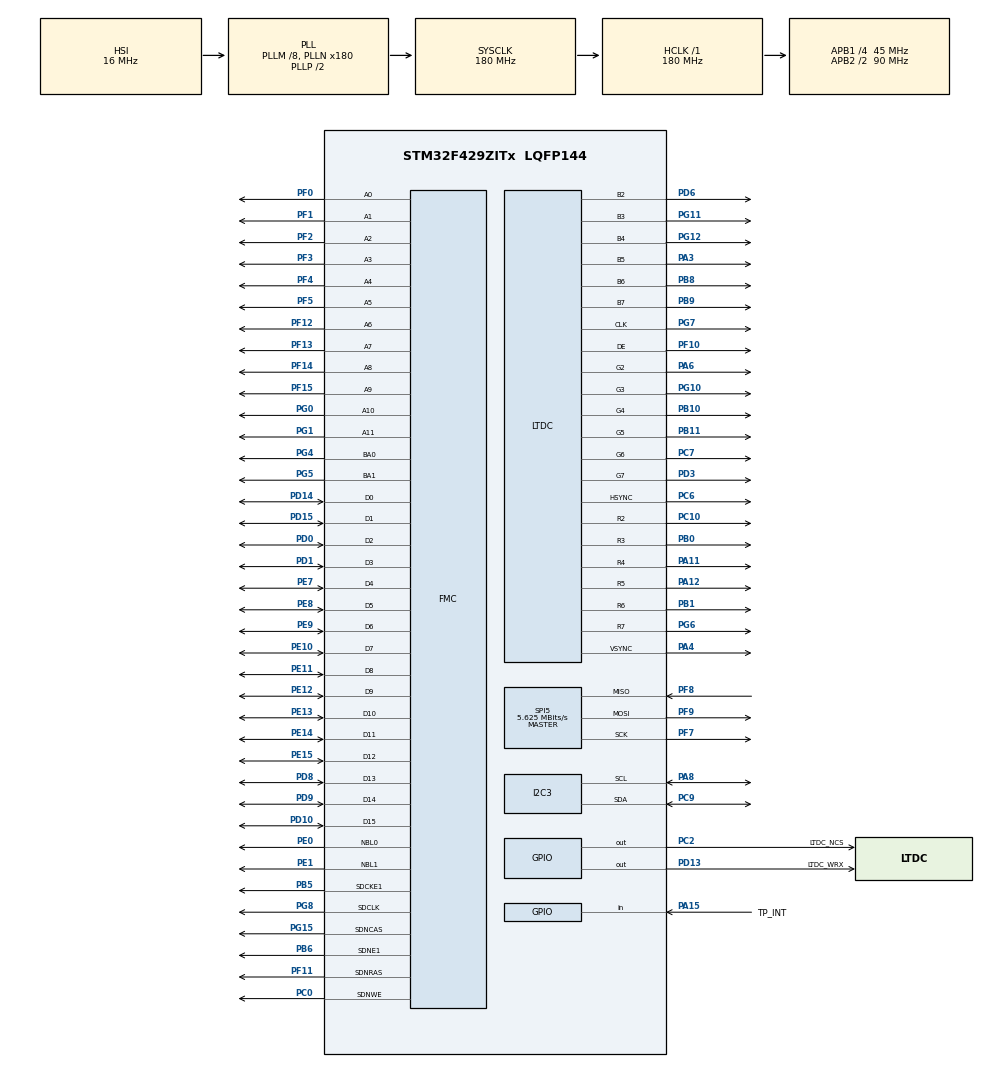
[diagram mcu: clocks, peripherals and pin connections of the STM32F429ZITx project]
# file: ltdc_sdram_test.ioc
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DMA2D.AlphaModeBackground=DMA2D_REPLACE_ALPHA
DMA2D.AlphaModeForeground=DMA2D_REPLACE_ALPHA
DMA2D.ColorMode=DMA2D_OUTPUT_RGB888
DMA2D.InputColorModeBackground=DMA2D_INPUT_RGB888
DMA2D.InputColorModeForeground=DMA2D_INPUT_RGB888
DMA2D.Mode=DMA2D_M2M_BLEND
FMC.CASLatency1=FMC_SDRAM_CAS_LATENCY_3
FMC.ExitSelfRefreshDelay1=7
FMC.LoadToActiveDelay1=2
FMC.RCDDelay1=2
FMC.RPDelay1=2
FMC.RPDelay2=2
FMC.ReadPipeDelay1=FMC_SDRAM_RPIPE_DELAY_1
FMC.ReadPipeDelay2=FMC_SDRAM_RPIPE_DELAY_1
FMC.RowCycleDelay1=7
FMC.RowCycleDelay2=7
FMC.SDClockPeriod1=FMC_SDRAM_CLOCK_PERIOD_2
FMC.SDClockPeriod2=FMC_SDRAM_CLOCK_PERIOD_2
FMC.SelfRefreshTime1=4
FMC.WriteRecoveryTime1=3
FREERTOS.Tasks01=defaultTask,0,128,StartDefaultTask,Default,NULL
I2C3.OwnAddress=0x41
LTDC.ActiveH=320
LTDC.ActiveW=240
LTDC.Alpha_L0=255
LTDC.BlendingFactor1_L0=LTDC_BLENDING_FACTOR1_CA
LTDC.BlendingFactor2_L0=LTDC_BLENDING_FACTOR2_CA
LTDC.HBP=21
LTDC.HFP=10
LTDC.HSync=9
LTDC.ImageHeight_L0=320
LTDC.ImageWidth_L0=240
LTDC.Layers=0
LTDC.PixelFormat_L0=LTDC_PIXEL_FORMAT_RGB888
LTDC.VBP=3
LTDC.VFP=4
LTDC.VSync=1
LTDC.WindowX1_L0=240
LTDC.WindowY1_L0=320
Mcu.Family=STM32F4
Mcu.Name=STM32F429ZITx
Mcu.Package=LQFP144
NVIC.DMA2D_IRQn=true\:5\:0\:false\:false\:true\:true\:true
NVIC.PriorityGroup=NVIC_PRIORITYGROUP_4
PA11.GPIO_Speed=GPIO_SPEED_FREQ_HIGH
PA11.Mode=RGB666
PA11.Signal=LTDC_R4
PA12.GPIO_Speed=GPIO_SPEED_FREQ_HIGH
PA12.Mode=RGB666
PA12.Signal=LTDC_R5
PA13.Mode=Serial_Wire
PA13.Signal=SYS_JTMS-SWDIO
PA14.Mode=Serial_Wire
PA14.Signal=SYS_JTCK-SWCLK
PA15.GPIO_Label=TP_INT
PA15.Signal=GPIO_Input
PA3.GPIO_Speed=GPIO_SPEED_FREQ_HIGH
PA3.Mode=RGB666
PA3.Signal=LTDC_B5
PA4.GPIO_Speed=GPIO_SPEED_FREQ_HIGH
PA4.Mode=RGB666
PA4.Signal=LTDC_VSYNC
PA6.GPIO_Speed=GPIO_SPEED_FREQ_HIGH
PA6.Mode=RGB666
PA6.Signal=LTDC_G2
PA8.Mode=I2C
PA8.Signal=I2C3_SCL
PB0.GPIO_Speed=GPIO_SPEED_FREQ_HIGH
PB0.Mode=RGB666
PB0.Signal=LTDC_R3
PB1.GPIO_Speed=GPIO_SPEED_FREQ_HIGH
PB1.Mode=RGB666
PB1.Signal=LTDC_R6
PB10.GPIO_Speed=GPIO_SPEED_FREQ_HIGH
PB10.Mode=RGB666
PB10.Signal=LTDC_G4
PB11.GPIO_Speed=GPIO_SPEED_FREQ_HIGH
PB11.Mode=RGB666
PB11.Signal=LTDC_G5
PB5.Mode=SdramChipSelect2_1
PB5.Signal=FMC_SDCKE1
PB6.Mode=SdramChipSelect2_1
PB6.Signal=FMC_SDNE1
PB8.GPIO_Speed=GPIO_SPEED_FREQ_HIGH
PB8.Mode=RGB666
PB8.Signal=LTDC_B6
PB9.GPIO_Speed=GPIO_SPEED_FREQ_HIGH
PB9.Mode=RGB666
PB9.Signal=LTDC_B7
PC0.Signal=FMC_SDNWE
PC10.GPIO_Speed=GPIO_SPEED_FREQ_HIGH
PC10.Mode=RGB666
PC10.Signal=LTDC_R2
PC2.GPIO_Label=LTDC_NCS
PC2.GPIO_Speed=GPIO_SPEED_FREQ_HIGH
PC2.PinState=GPIO_PIN_SET
PC2.Signal=GPIO_Output
PC6.GPIO_Speed=GPIO_SPEED_FREQ_HIGH
PC6.Mode=RGB666
PC6.Signal=LTDC_HSYNC
PC7.GPIO_Speed=GPIO_SPEED_FREQ_HIGH
PC7.Mode=RGB666
PC7.Signal=LTDC_G6
PC9.Mode=I2C
PC9.Signal=I2C3_SDA
PD0.Signal=FMC_D2_DA2
PD1.Signal=FMC_D3_DA3
PD10.Signal=FMC_D15_DA15
PD13.GPIO_Label=LTDC_WRX
PD13.GPIO_Speed=GPIO_SPEED_FREQ_HIGH
PD13.Signal=GPIO_Output
PD14.Signal=FMC_D0_DA0
PD15.Signal=FMC_D1_DA1
PD3.GPIO_Speed=GPIO_SPEED_FREQ_HIGH
PD3.Mode=RGB666
PD3.Signal=LTDC_G7
PD6.GPIO_Speed=GPIO_SPEED_FREQ_HIGH
PD6.Mode=RGB666
PD6.Signal=LTDC_B2
PD8.Signal=FMC_D13_DA13
PD9.Signal=FMC_D14_DA14
PE0.Signal=FMC_NBL0
PE1.Signal=FMC_NBL1
PE10.Signal=FMC_D7_DA7
PE11.Signal=FMC_D8_DA8
PE12.Signal=FMC_D9_DA9
PE13.Signal=FMC_D10_DA10
PE14.Signal=FMC_D11_DA11
PE15.Signal=FMC_D12_DA12
PE7.Signal=FMC_D4_DA4
PE8.Signal=FMC_D5_DA5
PE9.Signal=FMC_D6_DA6
PF0.Signal=FMC_A0
PF1.Signal=FMC_A1
PF10.GPIO_Speed=GPIO_SPEED_FREQ_HIGH
PF10.Mode=RGB666
PF10.Signal=LTDC_DE
PF11.Signal=FMC_SDNRAS
PF12.Signal=FMC_A6
PF13.Signal=FMC_A7
PF14.Signal=FMC_A8
PF15.Signal=FMC_A9
PF2.Signal=FMC_A2
PF3.Signal=FMC_A3
PF4.Signal=FMC_A4
PF5.Signal=FMC_A5
PF7.Mode=Full_Duplex_Master
PF7.Signal=SPI5_SCK
PF8.Mode=Full_Duplex_Master
PF8.Signal=SPI5_MISO
PF9.Mode=Full_Duplex_Master
PF9.Signal=SPI5_MOSI
PG0.Signal=FMC_A10
PG1.Signal=FMC_A11
PG10.GPIO_Speed=GPIO_SPEED_FREQ_HIGH
PG10.Mode=RGB666
PG10.Signal=LTDC_G3
PG11.GPIO_Speed=GPIO_SPEED_FREQ_HIGH
PG11.Mode=RGB666
PG11.Signal=LTDC_B3
PG12.GPIO_Speed=GPIO_SPEED_FREQ_HIGH
PG12.Mode=RGB666
PG12.Signal=LTDC_B4
PG15.Signal=FMC_SDNCAS
PG4.Signal=FMC_A14_BA0
PG5.Signal=FMC_A15_BA1
PG6.GPIO_Speed=GPIO_SPEED_FREQ_HIGH
PG6.Mode=RGB666
PG6.Signal=LTDC_R7
PG7.GPIO_Speed=GPIO_SPEED_FREQ_HIGH
PG7.Mode=RGB666
PG7.Signal=LTDC_CLK
PG8.Signal=FMC_SDCLK
ProjectManager.HeapSize=0x2000
ProjectManager.StackSize=0x4000
ProjectManager.TargetToolchain=TrueSTUDIO
RCC.48MHZClocksFreq_Value=90000000
RCC.AHBFreq_Value=180000000
RCC.APB1CLKDivider=RCC_HCLK_DIV4
RCC.APB1Freq_Value=45000000
RCC.APB1TimFreq_Value=90000000
RCC.APB2CLKDivider=RCC_HCLK_DIV2
RCC.APB2Freq_Value=90000000
RCC.APB2TimFreq_Value=180000000
RCC.CortexFreq_Value=180000000
RCC.HCLKFreq_Value=180000000
RCC.HSE_VALUE=25000000
RCC.HSI_VALUE=16000000
RCC.LSE_VALUE=32768
RCC.PLLM=8
RCC.PLLN=180
RCC.PLLSAIDivR=RCC_PLLSAIDIVR_4
RCC.PLLSAIN=60
RCC.SYSCLKFreq_VALUE=180000000
RCC.SYSCLKSource=RCC_SYSCLKSOURCE_PLLCLK
RCC.VCOOutputFreq_Value=360000000
SH.FMC_A0.0=FMC_A0,12b-sda1
SH.FMC_A1.0=FMC_A1,12b-sda1
SH.FMC_A10.0=FMC_A10,12b-sda1
SH.FMC_A11.0=FMC_A11,12b-sda1
SH.FMC_A14_BA0.0=FMC_BA0,FourSdramBanks1
SH.FMC_A15_BA1.0=FMC_BA1,FourSdramBanks1
SH.FMC_A2.0=FMC_A2,12b-sda1
SH.FMC_A3.0=FMC_A3,12b-sda1
SH.FMC_A4.0=FMC_A4,12b-sda1
SH.FMC_A5.0=FMC_A5,12b-sda1
SH.FMC_A6.0=FMC_A6,12b-sda1
SH.FMC_A7.0=FMC_A7,12b-sda1
SH.FMC_A8.0=FMC_A8,12b-sda1
SH.FMC_A9.0=FMC_A9,12b-sda1
SH.FMC_D0_DA0.0=FMC_D0,sd-16b-d1
SH.FMC_D10_DA10.0=FMC_D10,sd-16b-d1
SH.FMC_D11_DA11.0=FMC_D11,sd-16b-d1
SH.FMC_D12_DA12.0=FMC_D12,sd-16b-d1
SH.FMC_D13_DA13.0=FMC_D13,sd-16b-d1
SH.FMC_D14_DA14.0=FMC_D14,sd-16b-d1
SH.FMC_D15_DA15.0=FMC_D15,sd-16b-d1
SH.FMC_D1_DA1.0=FMC_D1,sd-16b-d1
SH.FMC_D2_DA2.0=FMC_D2,sd-16b-d1
SH.FMC_D3_DA3.0=FMC_D3,sd-16b-d1
SH.FMC_D4_DA4.0=FMC_D4,sd-16b-d1
SH.FMC_D5_DA5.0=FMC_D5,sd-16b-d1
SH.FMC_D6_DA6.0=FMC_D6,sd-16b-d1
SH.FMC_D7_DA7.0=FMC_D7,sd-16b-d1
SH.FMC_D8_DA8.0=FMC_D8,sd-16b-d1
SH.FMC_D9_DA9.0=FMC_D9,sd-16b-d1
SH.FMC_NBL0.0=FMC_NBL0,Sd2ByteEnable1
SH.FMC_NBL1.0=FMC_NBL1,Sd2ByteEnable1
SH.FMC_SDCLK.0=FMC_SDCLK,12b-sda1
SH.FMC_SDNCAS.0=FMC_SDNCAS,12b-sda1
SH.FMC_SDNRAS.0=FMC_SDNRAS,12b-sda1
SH.FMC_SDNWE.0=FMC_SDNWE,12b-sda1
SPI5.BaudRatePrescaler=SPI_BAUDRATEPRESCALER_16
SPI5.CalculateBaudRate=5.625 MBits/s
SPI5.Direction=SPI_DIRECTION_2LINES
SPI5.Mode=SPI_MODE_MASTER
SPI5.VirtualType=VM_MASTER
VP_DMA2D_VS_DMA2D.Mode=DMA2D_Activate
VP_FREERTOS_VS_ENABLE.Mode=Enabled
board=custom

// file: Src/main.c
/* USER CODE BEGIN Header */
/**
  ******************************************************************************
  * @file           : main.c
  * @brief          : Main program body
  ******************************************************************************
  ** This notice applies to any and all portions of this file
  * that are not between comment pairs USER CODE BEGIN and
  * USER CODE END. Other portions of this file, whether
  * inserted by the user or by software development tools
  * are owned by their respective copyright owners.
  *
  * COPYRIGHT(c) 2018 STMicroelectronics
  *
  * Redistribution and use in source and binary forms, with or without modification,
  * are permitted provided that the following conditions are met:
  *   1. Redistributions of source code must retain the above copyright notice,
  *      this list of conditions and the following disclaimer.
  *   2. Redistributions in binary form must reproduce the above copyright notice,
  *      this list of conditions and the following disclaimer in the documentation
  *      and/or other materials provided with the distribution.
  *   3. Neither the name of STMicroelectronics nor the names of its contributors
  *      may be used to endorse or promote products derived from this software
  *      without specific prior written permission.
  *
  * THIS SOFTWARE IS PROVIDED BY THE COPYRIGHT HOLDERS AND CONTRIBUTORS "AS IS"
  * AND ANY EXPRESS OR IMPLIED WARRANTIES, INCLUDING, BUT NOT LIMITED TO, THE
  * IMPLIED WARRANTIES OF MERCHANTABILITY AND FITNESS FOR A PARTICULAR PURPOSE ARE
  * DISCLAIMED. IN NO EVENT SHALL THE COPYRIGHT HOLDER OR CONTRIBUTORS BE LIABLE
  * FOR ANY DIRECT, INDIRECT, INCIDENTAL, SPECIAL, EXEMPLARY, OR CONSEQUENTIAL
  * DAMAGES (INCLUDING, BUT NOT LIMITED TO, PROCUREMENT OF SUBSTITUTE GOODS OR
  * SERVICES; LOSS OF USE, DATA, OR PROFITS; OR BUSINESS INTERRUPTION) HOWEVER
  * CAUSED AND ON ANY THEORY OF LIABILITY, WHETHER IN CONTRACT, STRICT LIABILITY,
  * OR TORT (INCLUDING NEGLIGENCE OR OTHERWISE) ARISING IN ANY WAY OUT OF THE USE
  * OF THIS SOFTWARE, EVEN IF ADVISED OF THE POSSIBILITY OF SUCH DAMAGE.
  *
  ******************************************************************************
  */
/* USER CODE END Header */

#include "main.h"
#include "cmsis_os.h"

/* USER CODE BEGIN Includes */
#include "ltdc.h"
#include "sdram.h"
#include "touch.h"
#include "GUI.h"
#include "WM.h"
#include "DIALOG.h"
#include "MESSAGEBOX.h"
/* USER CODE END Includes */

/* USER CODE BEGIN PD */
#define LCD_FRAME_BUFFER       ((uint32_t)0xD0000000)
#define BUFFER_OFFSET          ((uint32_t)0x50000)

/* USER CODE END PD */

//DMA2D_HandleTypeDef hdma2d;

I2C_HandleTypeDef hi2c3;

//LTDC_HandleTypeDef hltdc;

SPI_HandleTypeDef hspi5;

SDRAM_HandleTypeDef hsdram1;

osThreadId defaultTaskHandle;

void SystemClock_Config(void);
static void MX_GPIO_Init(void);
static void MX_SPI5_Init(void);
static void MX_FMC_Init(void);
static void MX_I2C3_Init(void);
void StartDefaultTask(void const * argument);

int main(void)
{

  /* MCU Configuration--------------------------------------------------------*/

  /* Reset of all peripherals, Initializes the Flash interface and the Systick. */
  HAL_Init();

  /* Configure the system clock */
  SystemClock_Config();

  /* Initialize all configured peripherals */
  MX_GPIO_Init();
  //MX_LTDC_Init();
  MX_SPI5_Init();
  MX_FMC_Init();
  //MX_DMA2D_Init();
  MX_I2C3_Init();
  /* USER CODE BEGIN 2 */
  SDRAM_init(&hsdram1);
  MyLCD_PowerOn();
  TP_Config();

  /* Enable CRC to Unlock GUI */
  __HAL_RCC_CRC_CLK_ENABLE();

  /* Enable Back up SRAM */
  __HAL_RCC_BKPSRAM_CLK_ENABLE();

  /* USER CODE END 2 */

  /* Create the thread(s) */
  /* definition and creation of defaultTask */
  osThreadDef(defaultTask, StartDefaultTask, osPriorityNormal, 0, 128);
  defaultTaskHandle = osThreadCreate(osThread(defaultTask), NULL);

  GUI_X_InitOS();

  /* Start scheduler */
  osKernelStart();

  /* We should never get here as control is now taken by the scheduler */

  /* Infinite loop */
  while (1)
  {

  }
}

extern GUI_BITMAP bmstickman_50x50;
extern GUI_CONST_STORAGE GUI_BITMAP bmfilebrowser;
extern GUI_CONST_STORAGE GUI_BITMAP _bmWhiteCircle_10x10;
extern GUI_CONST_STORAGE GUI_BITMAP _bmWhiteCircle_6x6;
extern GUI_CONST_STORAGE GUI_BITMAP bmSTLogo;

static uint32_t idx = 0;

static void _cb(WM_MESSAGE *pMsg)
{
	uint16_t   xPos, Step = 20, i;
	const GUI_BITMAP * pBm;

	switch (pMsg->MsgId)
	{
	case WM_PAINT:
	  GUI_SetBkColor(GUI_LIGHTBLUE);
	  GUI_Clear();

	  GUI_DrawBitmap(&bmSTLogo, (LCD_GetXSize() - bmSTLogo.XSize)/2 , (LCD_GetYSize() - bmSTLogo.YSize)/2);

	  for (i = 0, xPos = LCD_GetXSize() / 2 - 2 * Step; i < 5; i++, xPos += Step)
	  {
	    pBm = (idx == i) ? &_bmWhiteCircle_10x10 : &_bmWhiteCircle_6x6;
	    GUI_DrawBitmap(pBm, xPos - pBm->XSize / 2, 250 - pBm->YSize / 2);
	  }
	  break;

	default:
	  WM_DefaultProc(pMsg);
	}
}

void StartDefaultTask(void const * argument)
{
	GUI_Init();
	WM_MULTIBUF_Enable(1);
	GUI_SetBkColor(GUI_BLUE);
	GUI_Clear();
	GUI_MEMDEV_Handle hMemSource;
	GUI_MEMDEV_Handle hMemDest;
	GUI_RECT RectSource = {0, 0, 69, 39};
	GUI_RECT RectDest = {0, 0, 79, 79};
	hMemSource = GUI_MEMDEV_CreateFixed(RectSource.x0, RectSource.y0,
	 RectSource.x1 - RectSource.x0 + 1,
	 RectSource.y1 - RectSource.y0 + 1,
	 GUI_MEMDEV_NOTRANS,
	 GUI_MEMDEV_APILIST_32, GUI_COLOR_CONV_888);
	hMemDest = GUI_MEMDEV_CreateFixed(RectDest.x0, RectDest.y0,
	 RectDest.x1 - RectDest.x0 + 1,
	 RectDest.y1 - RectDest.y0 + 1,
	 GUI_MEMDEV_NOTRANS,
	 GUI_MEMDEV_APILIST_32, GUI_COLOR_CONV_888);
	GUI_MEMDEV_Select(hMemSource);
	GUI_DrawGradientV(RectSource.x0, RectSource.y0,
	 RectSource.x1, RectSource.y1,
	 GUI_WHITE, GUI_DARKGREEN);
	GUI_SetColor(GUI_BLUE);
	GUI_SetFont(&GUI_Font20B_ASCII);
	GUI_SetTextMode(GUI_TM_TRANS);
	GUI_DispStringInRect("emWin", &RectSource, GUI_TA_HCENTER | GUI_TA_VCENTER);
	GUI_DrawRect(0, 0, RectSource.x1, RectSource.y1);
	GUI_MEMDEV_Select(hMemDest);
	GUI_Clear();
	GUI_MEMDEV_Select(0);
	GUI_MEMDEV_RotateHQ(hMemSource, hMemDest,
	 (RectDest.x1 - RectSource.x1) / 2,
	 (RectDest.y1 - RectSource.y1) / 2,
	 90 * 1000,
	 0.9 * 1000);
	GUI_MEMDEV_CopyToLCDAt(hMemSource, 10, (RectDest.y1 - RectSource.y1) / 2);
	GUI_MEMDEV_CopyToLCDAt(hMemDest, 100, 0);

	HAL_Delay(1000);
	GUI_Clear();
	GUI_SetColor(GUI_YELLOW);
	GUI_AA_FillCircle(100, 150, 40);
	GUI_SetColor(GUI_ORANGE);
	GUI_FillCircle(150, 100, 40);
	GUI_SetColor(GUI_MAGENTA);
	GUI_FillRect(2, 2, 50, 50);
	GUI_DrawBitmap(&bmstickman_50x50, 50, 200);
	GUI_DrawBitmap(&bmfilebrowser, 100, 200);

	GUI_SetColor(GUI_DARKMAGENTA);
	GUI_SetFont(GUI_FONT_COMIC24B_ASCII);
	GUI_DispStringAt("Hello world!", 10, 10);

//	WM_SetCallback(WM_HBKWIN, _cb);
//	GUI_RECT Rect = {0, 0, 480, 272};
//	uint8_t loop = 16;
//	while (loop--)
//	{
//		idx = (16 - loop) % 5;
//		WM_InvalidateArea(&Rect);
//		GUI_Delay(500);
//	}
	while (1)
	{
		osDelay(10);
	}
	/* USER CODE END 5 */
}

void SystemClock_Config(void)
{
  RCC_OscInitTypeDef RCC_OscInitStruct = {0};
  RCC_ClkInitTypeDef RCC_ClkInitStruct = {0};
  RCC_PeriphCLKInitTypeDef PeriphClkInitStruct = {0};

  /**Configure the main internal regulator output voltage
  */
  __HAL_RCC_PWR_CLK_ENABLE();
  __HAL_PWR_VOLTAGESCALING_CONFIG(PWR_REGULATOR_VOLTAGE_SCALE1);
  /**Initializes the CPU, AHB and APB busses clocks
  */
  RCC_OscInitStruct.OscillatorType = RCC_OSCILLATORTYPE_HSI;
  RCC_OscInitStruct.HSIState = RCC_HSI_ON;
  RCC_OscInitStruct.HSICalibrationValue = RCC_HSICALIBRATION_DEFAULT;
  RCC_OscInitStruct.PLL.PLLState = RCC_PLL_ON;
  RCC_OscInitStruct.PLL.PLLSource = RCC_PLLSOURCE_HSI;
  RCC_OscInitStruct.PLL.PLLM = 8;
  RCC_OscInitStruct.PLL.PLLN = 180;
  RCC_OscInitStruct.PLL.PLLP = RCC_PLLP_DIV2;
  RCC_OscInitStruct.PLL.PLLQ = 4;
  if (HAL_RCC_OscConfig(&RCC_OscInitStruct) != HAL_OK)
  {
    Error_Handler();
  }
  /**Activate the Over-Drive mode
  */
  if (HAL_PWREx_EnableOverDrive() != HAL_OK)
  {
    Error_Handler();
  }
  /**Initializes the CPU, AHB and APB busses clocks
  */
  RCC_ClkInitStruct.ClockType = RCC_CLOCKTYPE_HCLK|RCC_CLOCKTYPE_SYSCLK
                              |RCC_CLOCKTYPE_PCLK1|RCC_CLOCKTYPE_PCLK2;
  RCC_ClkInitStruct.SYSCLKSource = RCC_SYSCLKSOURCE_PLLCLK;
  RCC_ClkInitStruct.AHBCLKDivider = RCC_SYSCLK_DIV1;
  RCC_ClkInitStruct.APB1CLKDivider = RCC_HCLK_DIV4;
  RCC_ClkInitStruct.APB2CLKDivider = RCC_HCLK_DIV2;

  if (HAL_RCC_ClockConfig(&RCC_ClkInitStruct, FLASH_LATENCY_5) != HAL_OK)
  {
    Error_Handler();
  }
  PeriphClkInitStruct.PeriphClockSelection = RCC_PERIPHCLK_LTDC;
  PeriphClkInitStruct.PLLSAI.PLLSAIN = 60;
  PeriphClkInitStruct.PLLSAI.PLLSAIR = 2;
  PeriphClkInitStruct.PLLSAIDivR = RCC_PLLSAIDIVR_4;
  if (HAL_RCCEx_PeriphCLKConfig(&PeriphClkInitStruct) != HAL_OK)
  {
    Error_Handler();
  }
}

//static void MX_DMA2D_Init(void)
//{
//
//  /* USER CODE BEGIN DMA2D_Init 0 */
//
//  /* USER CODE END DMA2D_Init 0 */
//
//  /* USER CODE BEGIN DMA2D_Init 1 */
//
//  /* USER CODE END DMA2D_Init 1 */
//  hdma2d.Instance = DMA2D;
//  hdma2d.Init.Mode = DMA2D_M2M_BLEND;
//  hdma2d.Init.ColorMode = DMA2D_OUTPUT_RGB888;
//  hdma2d.Init.OutputOffset = 0;
//  hdma2d.LayerCfg[0].InputOffset = 0;
//  hdma2d.LayerCfg[0].InputColorMode = DMA2D_INPUT_RGB888;
//  hdma2d.LayerCfg[0].AlphaMode = DMA2D_REPLACE_ALPHA;
//  hdma2d.LayerCfg[0].InputAlpha = 0;
//  hdma2d.LayerCfg[1].InputOffset = 0;
//  hdma2d.LayerCfg[1].InputColorMode = DMA2D_INPUT_RGB888;
//  hdma2d.LayerCfg[1].AlphaMode = DMA2D_REPLACE_ALPHA;
//  hdma2d.LayerCfg[1].InputAlpha = 0;
//  if (HAL_DMA2D_Init(&hdma2d) != HAL_OK)
//  {
//    Error_Handler();
//  }
//  if (HAL_DMA2D_ConfigLayer(&hdma2d, 0) != HAL_OK)
//  {
//    Error_Handler();
//  }
//  if (HAL_DMA2D_ConfigLayer(&hdma2d, 1) != HAL_OK)
//  {
//    Error_Handler();
//  }
//  /* USER CODE BEGIN DMA2D_Init 2 */
//
//  /* USER CODE END DMA2D_Init 2 */
//
//}

static void MX_I2C3_Init(void)
{

  hi2c3.Instance = I2C3;
  hi2c3.Init.ClockSpeed = 100000;
  hi2c3.Init.DutyCycle = I2C_DUTYCYCLE_2;
  hi2c3.Init.OwnAddress1 = 130;
  hi2c3.Init.AddressingMode = I2C_ADDRESSINGMODE_7BIT;
  hi2c3.Init.DualAddressMode = I2C_DUALADDRESS_DISABLE;
  hi2c3.Init.OwnAddress2 = 0;
  hi2c3.Init.GeneralCallMode = I2C_GENERALCALL_DISABLE;
  hi2c3.Init.NoStretchMode = I2C_NOSTRETCH_DISABLE;
  if (HAL_I2C_Init(&hi2c3) != HAL_OK)
  {
    Error_Handler();
  }
  /**Configure Analogue filter
  */
  if (HAL_I2CEx_ConfigAnalogFilter(&hi2c3, I2C_ANALOGFILTER_ENABLE) != HAL_OK)
  {
    Error_Handler();
  }
  /**Configure Digital filter
  */
  if (HAL_I2CEx_ConfigDigitalFilter(&hi2c3, 0) != HAL_OK)
  {
    Error_Handler();
  }

}

//static void MX_LTDC_Init(void)
//{
//
//  /* USER CODE BEGIN LTDC_Init 0 */
//
//  /* USER CODE END LTDC_Init 0 */
//
//  LTDC_LayerCfgTypeDef pLayerCfg = {0};
//
//  /* USER CODE BEGIN LTDC_Init 1 */
//
//  /* USER CODE END LTDC_Init 1 */
//  hltdc.Instance = LTDC;
//  hltdc.Init.HSPolarity = LTDC_HSPOLARITY_AL;
//  hltdc.Init.VSPolarity = LTDC_VSPOLARITY_AL;
//  hltdc.Init.DEPolarity = LTDC_DEPOLARITY_AL;
//  hltdc.Init.PCPolarity = LTDC_PCPOLARITY_IPC;
//  hltdc.Init.HorizontalSync = 8;
//  hltdc.Init.VerticalSync = 0;
//  hltdc.Init.AccumulatedHBP = 29;
//  hltdc.Init.AccumulatedVBP = 3;
//  hltdc.Init.AccumulatedActiveW = 269;
//  hltdc.Init.AccumulatedActiveH = 323;
//  hltdc.Init.TotalWidth = 279;
//  hltdc.Init.TotalHeigh = 327;
//  hltdc.Init.Backcolor.Blue = 0;
//  hltdc.Init.Backcolor.Green = 0;
//  hltdc.Init.Backcolor.Red = 0;
//  if (HAL_LTDC_Init(&hltdc) != HAL_OK)
//  {
//    Error_Handler();
//  }
//  pLayerCfg.WindowX0 = 0;
//  pLayerCfg.WindowX1 = 240;
//  pLayerCfg.WindowY0 = 0;
//  pLayerCfg.WindowY1 = 320;
//  pLayerCfg.PixelFormat = LTDC_PIXEL_FORMAT_RGB888;
//  pLayerCfg.Alpha = 255;
//  pLayerCfg.Alpha0 = 0;
//  pLayerCfg.BlendingFactor1 = LTDC_BLENDING_FACTOR1_CA;
//  pLayerCfg.BlendingFactor2 = LTDC_BLENDING_FACTOR2_CA;
//  pLayerCfg.FBStartAdress = 0;
//  pLayerCfg.ImageWidth = 240;
//  pLayerCfg.ImageHeight = 320;
//  pLayerCfg.Backcolor.Blue = 0;
//  pLayerCfg.Backcolor.Green = 0;
//  pLayerCfg.Backcolor.Red = 0;
//  if (HAL_LTDC_ConfigLayer(&hltdc, &pLayerCfg, 0) != HAL_OK)
//  {
//    Error_Handler();
//  }
//  /* USER CODE BEGIN LTDC_Init 2 */
//
//  /* USER CODE END LTDC_Init 2 */
//
//}

static void MX_SPI5_Init(void)
{

  /* SPI5 parameter configuration*/
  hspi5.Instance = SPI5;
  hspi5.Init.Mode = SPI_MODE_MASTER;
  hspi5.Init.Direction = SPI_DIRECTION_2LINES;
  hspi5.Init.DataSize = SPI_DATASIZE_8BIT;
  hspi5.Init.CLKPolarity = SPI_POLARITY_LOW;
  hspi5.Init.CLKPhase = SPI_PHASE_1EDGE;
  hspi5.Init.NSS = SPI_NSS_SOFT;
  hspi5.Init.BaudRatePrescaler = SPI_BAUDRATEPRESCALER_16;
  hspi5.Init.FirstBit = SPI_FIRSTBIT_MSB;
  hspi5.Init.TIMode = SPI_TIMODE_DISABLE;
  hspi5.Init.CRCCalculation = SPI_CRCCALCULATION_DISABLE;
  hspi5.Init.CRCPolynomial = 10;
  if (HAL_SPI_Init(&hspi5) != HAL_OK)
  {
    Error_Handler();
  }

}

/* FMC initialization function */
static void MX_FMC_Init(void)
{
  FMC_SDRAM_TimingTypeDef SdramTiming;

  /** Perform the SDRAM1 memory initialization sequence
  */
  hsdram1.Instance = FMC_SDRAM_DEVICE;
  /* hsdram1.Init */
  hsdram1.Init.SDBank = FMC_SDRAM_BANK2;
  hsdram1.Init.ColumnBitsNumber = FMC_SDRAM_COLUMN_BITS_NUM_8;
  hsdram1.Init.RowBitsNumber = FMC_SDRAM_ROW_BITS_NUM_12;
  hsdram1.Init.MemoryDataWidth = FMC_SDRAM_MEM_BUS_WIDTH_16;
  hsdram1.Init.InternalBankNumber = FMC_SDRAM_INTERN_BANKS_NUM_4;
  hsdram1.Init.CASLatency = FMC_SDRAM_CAS_LATENCY_3;
  hsdram1.Init.WriteProtection = FMC_SDRAM_WRITE_PROTECTION_DISABLE;
  hsdram1.Init.SDClockPeriod = FMC_SDRAM_CLOCK_PERIOD_2;
  hsdram1.Init.ReadBurst = FMC_SDRAM_RBURST_DISABLE;
  hsdram1.Init.ReadPipeDelay = FMC_SDRAM_RPIPE_DELAY_1;
  /* SdramTiming */
  SdramTiming.LoadToActiveDelay = 2;
  SdramTiming.ExitSelfRefreshDelay = 7;
  SdramTiming.SelfRefreshTime = 4;
  SdramTiming.RowCycleDelay = 7;
  SdramTiming.WriteRecoveryTime = 3;
  SdramTiming.RPDelay = 2;
  SdramTiming.RCDDelay = 2;

  if (HAL_SDRAM_Init(&hsdram1, &SdramTiming) != HAL_OK)
  {
    Error_Handler( );
  }

}

static void MX_GPIO_Init(void)
{
  GPIO_InitTypeDef GPIO_InitStruct = {0};

  /* GPIO Ports Clock Enable */
  __HAL_RCC_GPIOF_CLK_ENABLE();
  __HAL_RCC_GPIOC_CLK_ENABLE();
  __HAL_RCC_GPIOA_CLK_ENABLE();
  __HAL_RCC_GPIOB_CLK_ENABLE();
  __HAL_RCC_GPIOG_CLK_ENABLE();
  __HAL_RCC_GPIOE_CLK_ENABLE();
  __HAL_RCC_GPIOD_CLK_ENABLE();

  /*Configure GPIO pin Output Level */
  HAL_GPIO_WritePin(LTDC_NCS_GPIO_Port, LTDC_NCS_Pin, GPIO_PIN_SET);

  /*Configure GPIO pin Output Level */
  HAL_GPIO_WritePin(LTDC_WRX_GPIO_Port, LTDC_WRX_Pin, GPIO_PIN_RESET);

  /*Configure GPIO pin : LTDC_NCS_Pin */
  GPIO_InitStruct.Pin = LTDC_NCS_Pin;
  GPIO_InitStruct.Mode = GPIO_MODE_OUTPUT_PP;
  GPIO_InitStruct.Pull = GPIO_NOPULL;
  GPIO_InitStruct.Speed = GPIO_SPEED_FREQ_HIGH;
  HAL_GPIO_Init(LTDC_NCS_GPIO_Port, &GPIO_InitStruct);

  /*Configure GPIO pin : LTDC_WRX_Pin */
  GPIO_InitStruct.Pin = LTDC_WRX_Pin;
  GPIO_InitStruct.Mode = GPIO_MODE_OUTPUT_PP;
  GPIO_InitStruct.Pull = GPIO_NOPULL;
  GPIO_InitStruct.Speed = GPIO_SPEED_FREQ_HIGH;
  HAL_GPIO_Init(LTDC_WRX_GPIO_Port, &GPIO_InitStruct);

  /*Configure GPIO pin : TP_INT_Pin */
  GPIO_InitStruct.Pin = TP_INT_Pin;
  GPIO_InitStruct.Mode = GPIO_MODE_INPUT;
  GPIO_InitStruct.Pull = GPIO_NOPULL;
  HAL_GPIO_Init(TP_INT_GPIO_Port, &GPIO_InitStruct);

}

void Error_Handler(void)
{
}

/************************ (C) COPYRIGHT STMicroelectronics *****END OF FILE****/
